VERSION ""

NS_ :

BS_:

BU_: Gateway RearData_Module04 FrontData_Module01 MegaSniffer_Module02 EngineDataExtra_Module03

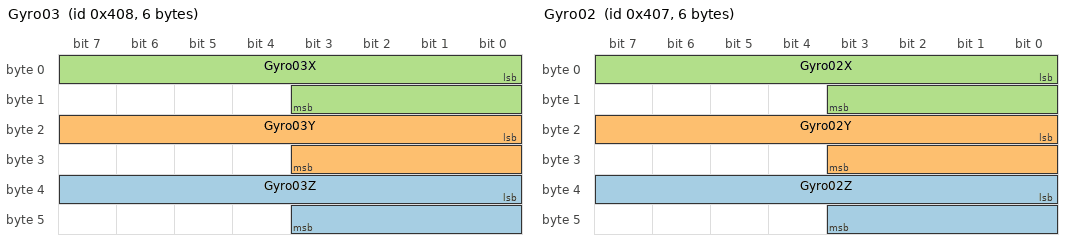
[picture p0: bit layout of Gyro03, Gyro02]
BO_ 1032 Gyro03: 6 RearData_Module04
 SG_ Gyro03Z : 32|12@1- (0.125,0) [-256|255.875] "deg/s"  Gateway
 SG_ Gyro03Y : 16|12@1- (0.125,0) [-256|255.875] "deg/s"  Gateway
 SG_ Gyro03X : 0|12@1- (0.125,0) [-256|255.875] "deg/s"  Gateway

BO_ 1031 Gyro02: 6 FrontData_Module01
 SG_ Gyro02Z : 32|12@1- (0.125,0) [-256|255.875] "deg/s"  Gateway
 SG_ Gyro02Y : 16|12@1- (0.125,0) [-256|255.875] "deg/s"  Gateway
 SG_ Gyro02X : 0|12@1- (0.125,0) [-256|255.875] "deg/s"  Gateway

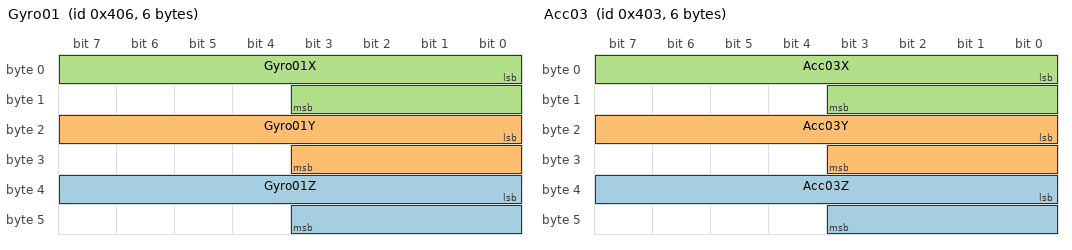
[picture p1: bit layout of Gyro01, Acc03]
BO_ 1030 Gyro01: 6 FrontData_Module01
 SG_ Gyro01Z : 32|12@1- (0.125,0) [-256|255.875] "deg/s"  Gateway
 SG_ Gyro01Y : 16|12@1- (0.125,0) [-256|255.875] "deg/s"  Gateway
 SG_ Gyro01X : 0|12@1- (0.125,0) [-256|255.875] "deg/s"  Gateway

BO_ 258 MAP: 2 MegaSniffer_Module02
 SG_ MAP : 0|10@1+ (250,0) [0|255750] "Pa"  Gateway

BO_ 1028 SuspFront: 4 FrontData_Module01
 SG_ SuspFrontRight : 16|10@1+ (1,0) [0|0] ""  Gateway
 SG_ SuspFrontLeft : 0|10@1+ (0.088,0) [0|90.024] "deg"  Gateway

BO_ 259 TPS: 1 MegaSniffer_Module02
 SG_ TPS : 0|8@1+ (1,0) [0|255] "%"  Gateway

BO_ 518 WaterTemp: 1 MegaSniffer_Module02
 SG_ WaterTemp : 0|8@1+ (1,0) [0|255] "degC"  Gateway

BO_ 513 AirTemp: 1 MegaSniffer_Module02
 SG_ AirTemp : 0|8@1+ (1,0) [0|255] "degC"  Gateway

BO_ 769 Speed: 1 RearData_Module04
 SG_ Speed : 0|8@1+ (1,0) [0|255] "km/h"  Gateway

BO_ 515 OilTemp: 1 RearData_Module04
 SG_ OilTemp : 0|8@1+ (1,0) [0|255] "degC"  Gateway

BO_ 1 OilPressure: 1 RearData_Module04
 SG_ OilPressure : 0|8@1+ (0.0392,0) [0|9.996] "Bar"  Gateway

BO_ 1029 SuspRear: 4 RearData_Module04
 SG_ SuspRearRight : 16|10@1+ (1,0) [0|0] ""  Gateway
 SG_ SuspRearLeft : 0|10@1+ (1,0) [0|0] ""  Gateway

BO_ 516 Pressure: 1 EngineDataExtra_Module03

BO_ 517 Temperature: 1 EngineDataExtra_Module03

BO_ 514 GearPosition: 1 EngineDataExtra_Module03
 SG_ GearPosition : 0|8@1+ (1,0) [0|6] "Gear"  Gateway

BO_ 257 Lambda: 1 MegaSniffer_Module02
 SG_ Lambda : 0|8@1+ (0.01,0) [0|2.55] ""  Gateway

BO_ 2 RPM: 2 MegaSniffer_Module02
 SG_ RPM : 0|16@1+ (1,0) [0|13000] "RPM"  Gateway

BO_ 1027 Acc03: 6 RearData_Module04
 SG_ Acc03Z : 32|12@1- (0.002,0) [-4.096|4.094] "G"  Gateway
 SG_ Acc03Y : 16|12@1- (0.002,0) [-4.096|4.094] "G"  Gateway
 SG_ Acc03X : 0|12@1- (0.002,0) [-4.096|4.094] "G"  Gateway

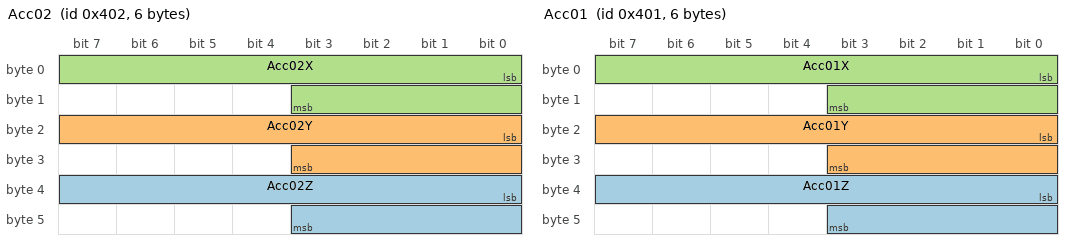
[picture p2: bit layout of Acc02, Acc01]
BO_ 1026 Acc02: 6 FrontData_Module01
 SG_ Acc02Z : 32|12@1- (0.002,0) [-4.096|4.094] "G"  Gateway
 SG_ Acc02Y : 16|12@1- (0.002,0) [-4.096|4.094] "G"  Gateway
 SG_ Acc02X : 0|12@1- (0.002,0) [-4.096|4.094] "G"  Gateway

BO_ 1025 Acc01: 6 FrontData_Module01
 SG_ Acc01Z : 32|12@1- (0.002,0) [-4.096|4.094] "G"  Gateway
 SG_ Acc01Y : 16|12@1- (0.002,0) [-4.096|4.094] "G"  Gateway
 SG_ Acc01X : 0|12@1- (0.002,0) [-4.096|4.094] "G"  Gateway

BA_DEF_  "BusType" STRING ;
BA_DEF_DEF_  "BusType" "CAN";
